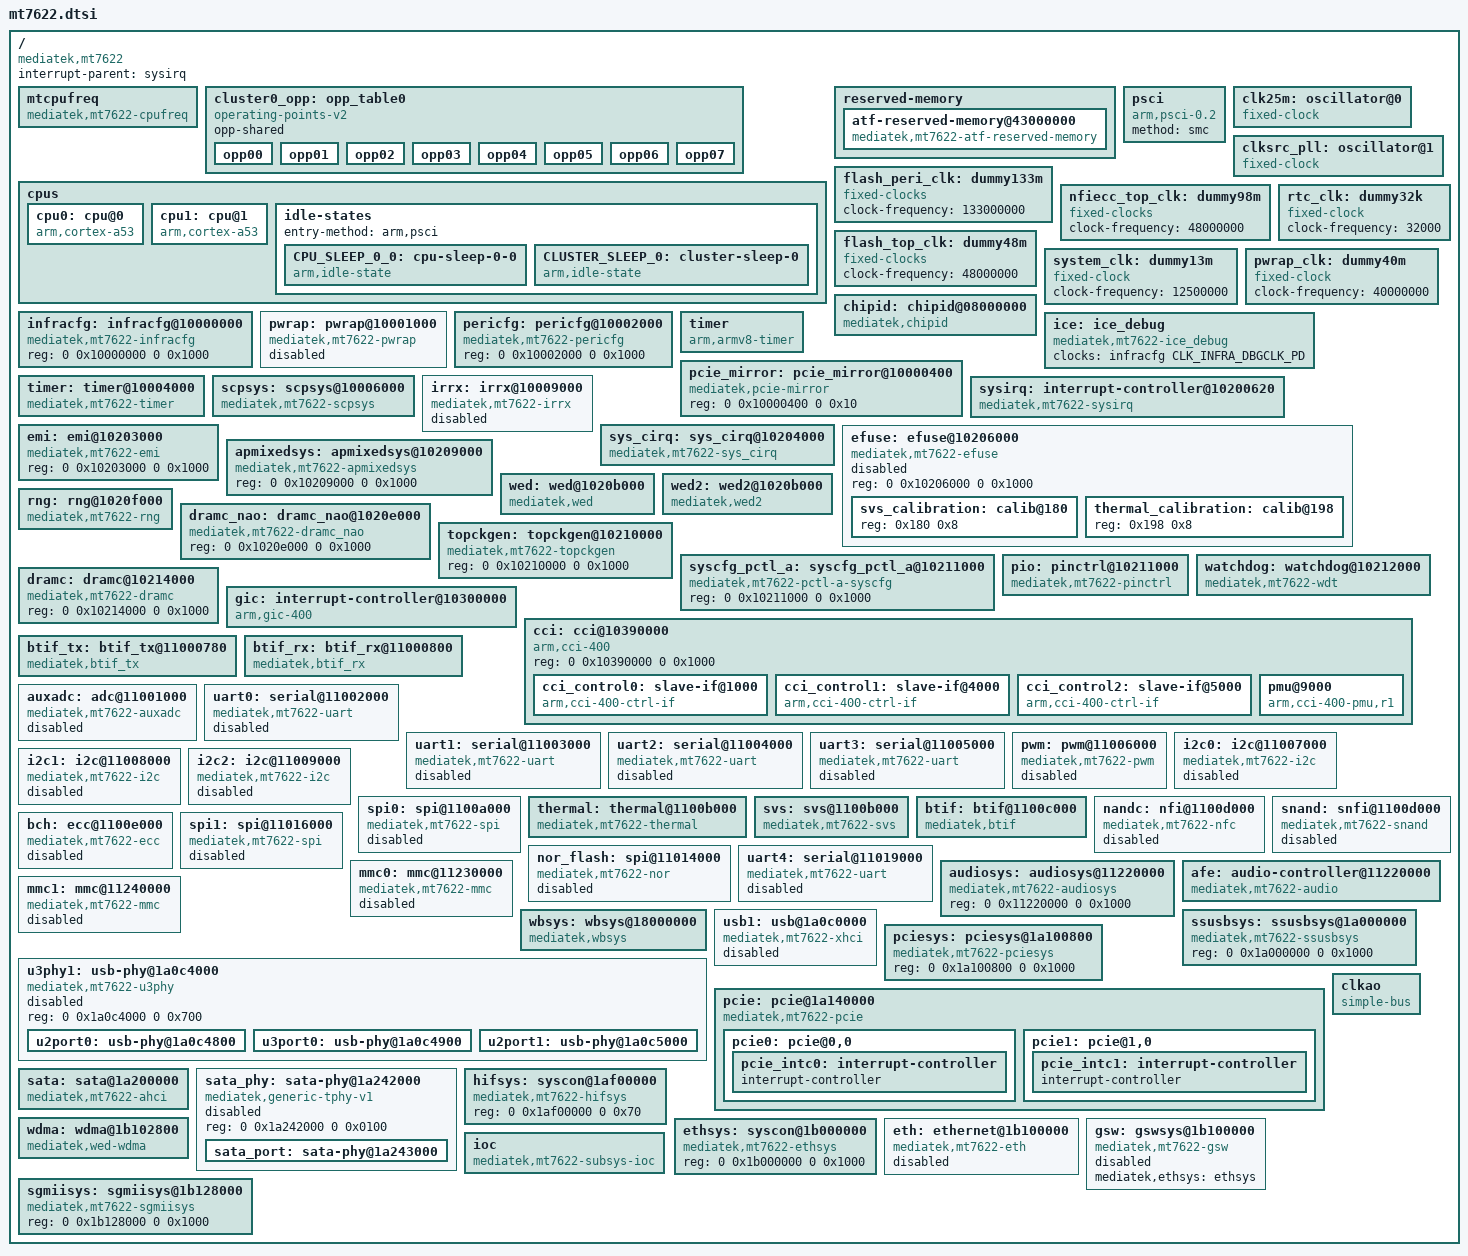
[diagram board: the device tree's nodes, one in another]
/*
 * Copyright (c) 2016 MediaTek Inc.
 * Author: Ming.Huang <ming.huang@mediatek.com>
 *
 * This program is free software; you can redistribute it and/or modify
 * it under the terms of the GNU General Public License version 2 as
 * published by the Free Software Foundation.
 *
 * This program is distributed in the hope that it will be useful,
 * but WITHOUT ANY WARRANTY; without even the implied warranty of
 * MERCHANTABILITY or FITNESS FOR A PARTICULAR PURPOSE.  See the
 * GNU General Public License for more details.
 */

#include <dt-bindings/clock/mt7622-clk.h>
#include <dt-bindings/interrupt-controller/irq.h>
#include <dt-bindings/interrupt-controller/arm-gic.h>
#include <dt-bindings/power/mt7622-power.h>
#include <dt-bindings/reset-controller/mt7622-resets.h>
#include <dt-bindings/phy/phy.h>
#include "mt7622-pinfunc.h"

/ {
	compatible = "mediatek,mt7622";
	interrupt-parent = <&sysirq>;
	#address-cells = <2>;
	#size-cells = <2>;

	mtcpufreq {
		compatible = "mediatek,mt7622-cpufreq";
	};

	cluster0_opp: opp_table0 {
		compatible = "operating-points-v2";
		opp-shared;
		opp00 {
			opp-hz = /bits/ 64 <300000000>;
			opp-microvolt = <950000>;
		};
		opp01 {
			opp-hz = /bits/ 64 <437500000>;
			opp-microvolt = <1000000>;
		};
		opp02 {
			opp-hz = /bits/ 64 <600000000>;
			opp-microvolt = <1050000>;
		};
		opp03 {
			opp-hz = /bits/ 64 <812500000>;
			opp-microvolt = <1100000>;
		};
		opp04 {
			opp-hz = /bits/ 64 <1025000000>;
			opp-microvolt = <1150000>;
		};
		opp05 {
			opp-hz = /bits/ 64 <1137500000>;
			opp-microvolt = <1200000>;
		};
		opp06 {
			opp-hz = /bits/ 64 <1262500000>;
			opp-microvolt = <1250000>;
		};
		opp07 {
			opp-hz = /bits/ 64 <1350000000>;
			opp-microvolt = <1310000>;
		};
	};

	cpus {
		#address-cells = <2>;
		#size-cells = <0>;

		cpu0: cpu@0 {
			device_type = "cpu";
			compatible = "arm,cortex-a53";
			reg = <0x0 0x0>;
			enable-method = "psci";
			cpu-idle-states = <&CLUSTER_SLEEP_0 &CLUSTER_SLEEP_0>,
				<&CPU_SLEEP_0_0 &CPU_SLEEP_0_0 &CPU_SLEEP_0_0>;
			clocks = <&infracfg CLK_INFRA_MUX1_SEL>,
				<&apmixedsys CLK_APMIXED_MAIN_CORE_EN>,
				<&apmixedsys CLK_APMIXED_ARMPLL>;
			clock-names = "cpu", "intermediate", "armpll";
			operating-points-v2 = <&cluster0_opp>;
			cpu-release-addr = <0x0 0x40000200>;
			clock-frequency = <1300000000>;
			cci-control-port = <&cci_control2>;
		};

		cpu1: cpu@1 {
			device_type = "cpu";
			compatible = "arm,cortex-a53";
			reg = <0x0 0x1>;
			enable-method = "psci";
			cpu-idle-states = <&CLUSTER_SLEEP_0 &CLUSTER_SLEEP_0>,
				<&CPU_SLEEP_0_0 &CPU_SLEEP_0_0 &CPU_SLEEP_0_0>;
			clocks = <&infracfg CLK_INFRA_MUX1_SEL>,
				<&apmixedsys CLK_APMIXED_MAIN_CORE_EN>,
				<&apmixedsys CLK_APMIXED_ARMPLL>;
			clock-names = "cpu", "intermediate", "armpll";
			operating-points-v2 = <&cluster0_opp>;
			cpu-release-addr = <0x0 0x40000200>;
			clock-frequency = <1300000000>;
			cci-control-port = <&cci_control2>;
		};

		idle-states {
			entry-method = "arm,psci";

			CPU_SLEEP_0_0: cpu-sleep-0-0 {
				compatible = "arm,idle-state";
				arm,psci-suspend-param = <0x0010000>;
				entry-latency-us = <600>;
				exit-latency-us = <600>;
				min-residency-us = <1200>;
			};

			CLUSTER_SLEEP_0: cluster-sleep-0 {
				compatible = "arm,idle-state";
				arm,psci-suspend-param = <0x1010000>;
				entry-latency-us = <800>;
				exit-latency-us = <1000>;
				min-residency-us = <2000>;
			};

		};
	};

	reserved-memory {
		#address-cells = <2>;
		#size-cells = <2>;
		ranges;

		atf-reserved-memory@43000000 {
			compatible = "mediatek,mt7622-atf-reserved-memory";
			no-map;
			reg = <0 0x43000000 0 0x100000>;
		};
	};

	psci {
		compatible  = "arm,psci-0.2";
		method      = "smc";
	};

	clk25m: oscillator@0 {
		compatible = "fixed-clock";
		#clock-cells = <0>;
		clock-frequency = <25000000>;
		clock-output-names = "clkxtal";
	};

	clksrc_pll: oscillator@1 {
		compatible = "fixed-clock";
		#clock-cells = <0>;
		clock-frequency = <25000000>;
		clock-output-names = "clksrc_pll";
	};

	flash_peri_clk: dummy133m {
		compatible = "fixed-clocks";
		clock-frequency = <133000000>;
		#clock-cells = <0>;
	};

	nfiecc_top_clk: dummy98m {
		compatible = "fixed-clocks";
		clock-frequency = <48000000>;
		#clock-cells = <0>;
	};

	flash_top_clk: dummy48m {
		compatible = "fixed-clocks";
		clock-frequency = <48000000>;
		#clock-cells = <0>;
	};

	system_clk: dummy13m {
		compatible = "fixed-clock";
		clock-frequency = <12500000>;
		#clock-cells = <0>;
	};

	rtc_clk: dummy32k {
		compatible = "fixed-clock";
		clock-frequency = <32000>;
		#clock-cells = <0>;
	};

	pwrap_clk: dummy40m {
		compatible = "fixed-clock";
		clock-frequency = <40000000>;
		#clock-cells = <0>;
	};

	chipid: chipid@08000000 {
		compatible = "mediatek,chipid";
		reg = <0 0x08000000 0 0x0004>,
		      <0 0x08000004 0 0x0004>,
		      <0 0x08000008 0 0x0004>,
		      <0 0x0800000c 0 0x0004>;
	};

	infracfg: infracfg@10000000 {
		compatible = "mediatek,mt7622-infracfg", "syscon";
		reg = <0 0x10000000 0 0x1000>;
		#clock-cells = <1>;
	};

	pwrap: pwrap@10001000 {
		compatible = "mediatek,mt7622-pwrap";
		reg = <0 0x10001000 0 0x250>;
		reg-names = "pwrap";
		clocks = <&infracfg CLK_INFRA_PMIC_PD>,<&pwrap_clk>;
		clock-names = "spi","wrap";
		status = "disabled";
	};

	pericfg: pericfg@10002000 {
		compatible = "mediatek,mt7622-pericfg", "syscon";
		reg = <0 0x10002000 0 0x1000>;
		#clock-cells = <1>;
	};

	ice: ice_debug {
		compatible ="mediatek,mt7622-ice_debug",
			    "mediatek,mt2701-ice_debug";
		clocks = <&infracfg CLK_INFRA_DBGCLK_PD>;
		clock-names = "ice_dbg";
	};

	timer {
		compatible = "arm,armv8-timer";
		interrupt-parent = <&gic>;
		interrupts = <GIC_PPI 13 (GIC_CPU_MASK_SIMPLE(4) | IRQ_TYPE_LEVEL_HIGH)>,
			     <GIC_PPI 14 (GIC_CPU_MASK_SIMPLE(4) | IRQ_TYPE_LEVEL_HIGH)>,
			     <GIC_PPI 11 (GIC_CPU_MASK_SIMPLE(4) | IRQ_TYPE_LEVEL_HIGH)>,
			     <GIC_PPI 10 (GIC_CPU_MASK_SIMPLE(4) | IRQ_TYPE_LEVEL_HIGH)>;
	};

	pcie_mirror: pcie_mirror@10000400 {
		compatible = "mediatek,pcie-mirror";
		reg = <0 0x10000400 0 0x10>;
	};

	timer: timer@10004000 {
		compatible = "mediatek,mt7622-timer",
			     "mediatek,mt6577-timer";
		reg = <0 0x10004000 0 0x80>;
		interrupts = <GIC_SPI 152 IRQ_TYPE_LEVEL_LOW>;
		clocks = <&infracfg CLK_INFRA_APXGPT_PD>, <&topckgen CLK_TOP_RTC>;
		clock-names = "system-clk", "rtc-clk";
	};

	scpsys: scpsys@10006000 {
		compatible = "mediatek,mt7622-scpsys", "syscon";
		#power-domain-cells = <1>;
		reg = <0 0x10006000 0 0x1000>;
		interrupts = <GIC_SPI 165 IRQ_TYPE_LEVEL_LOW>,
			     <GIC_SPI 166 IRQ_TYPE_LEVEL_LOW>,
			     <GIC_SPI 167 IRQ_TYPE_LEVEL_LOW>,
			     <GIC_SPI 168 IRQ_TYPE_LEVEL_LOW>;
		infracfg = <&infracfg>;
		clocks = <&topckgen CLK_TOP_RTC>, <&topckgen CLK_TOP_HIF_SEL>;
		clock-names = "spm_rtc", "hif_sel";
	};

	irrx: irrx@10009000 {
		compatible = "mediatek,mt7622-irrx";
		reg = <0 0x10009000 0 0x1000>;
		interrupts = <GIC_SPI 175 IRQ_TYPE_LEVEL_LOW>;
		clocks = <&infracfg CLK_INFRA_IRRX_PD>;
		clock-names = "irrx_clock";
		status = "disabled";
	};

	sysirq: interrupt-controller@10200620 {
		compatible = "mediatek,mt7622-sysirq",
			     "mediatek,mt6577-sysirq";
		interrupt-controller;
		#interrupt-cells = <3>;
		interrupt-parent = <&gic>;
		reg = <0 0x10200620 0 0x20>;
	};

	emi: emi@10203000 {
		compatible = "mediatek,mt7622-emi",
			     "mediatek,mt8127-emi";
		reg = <0 0x10203000 0 0x1000>;
	};

	sys_cirq: sys_cirq@10204000 {
		compatible = "mediatek,mt7622-sys_cirq",
			     "mediatek,sys_cirq";
		reg = <0 0x10204000 0 0x1000>;
		interrupts = <GIC_SPI 231 IRQ_TYPE_LEVEL_LOW>;
		mediatek,cirq_num = <169>;
		mediatek,spi_start_offset = <72>;
	};

	efuse: efuse@10206000 {
		compatible = "mediatek,mt7622-efuse",
			     "mediatek,efuse";
		reg = <0 0x10206000 0 0x1000>;
		#address-cells = <1>;
		#size-cells = <1>;
		status = "disabled";
		svs_calibration: calib@180 {
			reg = <0x180 0x8>;
		};
		thermal_calibration: calib@198 {
			reg = <0x198 0x8>;
		};
	};

	apmixedsys: apmixedsys@10209000 {
		compatible = "mediatek,mt7622-apmixedsys", "syscon";
		reg = <0 0x10209000 0 0x1000>;
		#clock-cells = <1>;
	};

	wed: wed@1020b000 {
		compatible = "mediatek,wed";
		wed_num = <2>;
		/* add this property for wed get the pci slot number. */
		pci_slot_map = <0>, <1>;
		reg = <0 0x1020a000 0 0x1000>,
		      <0 0x1020b000 0 0x1000>;
		interrupts = <GIC_SPI 214 IRQ_TYPE_LEVEL_LOW>,
			     <GIC_SPI 215 IRQ_TYPE_LEVEL_LOW>;
	};

	wed2: wed2@1020b000 {
		compatible = "mediatek,wed2";
		wed_num = <2>;
		reg = <0 0x1020a000 0 0x1000>,
		      <0 0x1020b000 0 0x1000>;
		interrupts = <GIC_SPI 214 IRQ_TYPE_LEVEL_LOW>,
			     <GIC_SPI 215 IRQ_TYPE_LEVEL_LOW>;
	};

	rng: rng@1020f000 {
		compatible = "mediatek,mt7622-rng",
			     "mediatek,mt7623-rng";
		reg = <0 0x1020f000 0 0x100>;
		clocks = <&infracfg CLK_INFRA_TRNG_PD>;
		clock-names = "rng";
	};

	dramc_nao: dramc_nao@1020e000 {
		compatible = "mediatek,mt7622-dramc_nao";
		reg = <0 0x1020e000 0 0x1000>;
	};

	topckgen: topckgen@10210000 {
		compatible = "mediatek,mt7622-topckgen", "syscon";
		reg = <0 0x10210000 0 0x1000>;
		#clock-cells = <1>;
	};

	syscfg_pctl_a: syscfg_pctl_a@10211000 {
			compatible = "mediatek,mt7622-pctl-a-syscfg", "syscon";
			reg = <0 0x10211000 0 0x1000>;
	};

	pio: pinctrl@10211000 {
			compatible = "mediatek,mt7622-pinctrl";
			reg = <0 0x10005000 0 0x1000>;
			mediatek,pctl-regmap = <&syscfg_pctl_a>;
			pins-are-numbered;
			gpio-controller;
			#gpio-cells = <2>;
			interrupt-controller;
			#interrupt-cells = <2>;
			interrupts = <GIC_SPI 153 IRQ_TYPE_LEVEL_HIGH>;
	};

	watchdog: watchdog@10212000 {
		compatible = "mediatek,mt7622-wdt",
			     "mediatek,mt6589-wdt";
		reg = <0 0x10212000 0 0x1000>;
		interrupts = <GIC_SPI 128 IRQ_TYPE_EDGE_FALLING>;
		#reset-cells = <1>;
	};

	dramc: dramc@10214000 {
		compatible = "mediatek,mt7622-dramc";
		reg = <0 0x10214000 0 0x1000>;
	};

	gic: interrupt-controller@10300000 {
		compatible = "arm,gic-400";
		interrupt-controller;
		#interrupt-cells = <3>;
		interrupt-parent = <&gic>;
		reg = <0 0x10310000 0 0x1000>,
		      <0 0x10320000 0 0x1000>,
		      <0 0x10340000 0 0x2000>,
		      <0 0x10360000 0 0x2000>;
	};

	cci: cci@10390000 {
		compatible = "arm,cci-400";
		#address-cells = <1>;
		#size-cells = <1>;
		reg = <0 0x10390000 0 0x1000>;
		ranges = <0 0 0x10390000 0x10000>;

		cci_control0: slave-if@1000 {
			compatible = "arm,cci-400-ctrl-if";
			interface-type = "ace-lite";
			reg = <0x1000 0x1000>;
		};

		cci_control1: slave-if@4000 {
			compatible = "arm,cci-400-ctrl-if";
			interface-type = "ace";
			reg = <0x4000 0x1000>;
		};

		cci_control2: slave-if@5000 {
			compatible = "arm,cci-400-ctrl-if";
			interface-type = "ace";
			reg = <0x5000 0x1000>;
		};

		pmu@9000 {
			compatible = "arm,cci-400-pmu,r1";
			reg = <0x9000 0x5000>;
			interrupts = <GIC_SPI 90 IRQ_TYPE_LEVEL_LOW>,
				     <GIC_SPI 91 IRQ_TYPE_LEVEL_LOW>,
				     <GIC_SPI 92 IRQ_TYPE_LEVEL_LOW>,
				     <GIC_SPI 93 IRQ_TYPE_LEVEL_LOW>,
				     <GIC_SPI 94 IRQ_TYPE_LEVEL_LOW>;
		};
	};

	btif_tx: btif_tx@11000780 {
		compatible = "mediatek,btif_tx";
		reg = <0 0x11000780 0 0x80>;
		interrupts = <GIC_SPI 111 IRQ_TYPE_LEVEL_LOW>;
	};

	btif_rx: btif_rx@11000800 {
		compatible = "mediatek,btif_rx";
		reg = <0 0x11000800 0 0x80>;
		interrupts = <GIC_SPI 112 IRQ_TYPE_LEVEL_LOW>;
	};

	auxadc: adc@11001000 {
		compatible = "mediatek,mt7622-auxadc";
		reg = <0 0x11001000 0 0x1000>;
		clocks = <&pericfg CLK_PERI_AUXADC_PD>;
		clock-names = "main";
		#io-channel-cells = <1>;
		status = "disabled";
	};

	uart0: serial@11002000 {
		compatible = "mediatek,mt7622-uart",
			     "mediatek,mt6577-uart";
		reg = <0 0x11002000 0 0x400>;
		interrupts = <GIC_SPI 91 IRQ_TYPE_LEVEL_LOW>;
		clocks = <&topckgen CLK_TOP_UART_SEL>, <&pericfg CLK_PERI_UART0_PD>;
		clock-names = "baud", "bus";
		status = "disabled";
	};

	uart1: serial@11003000 {
		compatible = "mediatek,mt7622-uart",
			     "mediatek,mt6577-uart";
		reg = <0 0x11003000 0 0x400>;
		interrupts = <GIC_SPI 92 IRQ_TYPE_LEVEL_LOW>;
		clocks = <&topckgen CLK_TOP_UART_SEL>, <&pericfg CLK_PERI_UART1_PD>;
		clock-names = "baud", "bus";
		status = "disabled";
	};

	uart2: serial@11004000 {
		compatible = "mediatek,mt7622-uart",
			     "mediatek,mt6577-uart";
		reg = <0 0x11004000 0 0x400>;
		interrupts = <GIC_SPI 93 IRQ_TYPE_LEVEL_LOW>;
		clocks = <&topckgen CLK_TOP_UART_SEL>, <&pericfg CLK_PERI_UART2_PD>;
		clock-names = "baud", "bus";
		status = "disabled";
	};

	uart3: serial@11005000 {
		compatible = "mediatek,mt7622-uart",
			     "mediatek,mt6577-uart";
		reg = <0 0x11005000 0 0x400>;
		interrupts = <GIC_SPI 94 IRQ_TYPE_LEVEL_LOW>;
		clocks = <&topckgen CLK_TOP_UART_SEL>, <&pericfg CLK_PERI_UART3_PD>;
		clock-names = "baud", "bus";
		status = "disabled";
	};


	pwm: pwm@11006000 {
		compatible = "mediatek,mt7622-pwm";
		reg = <0 0x11006000 0 0x1000>;
		interrupts = <GIC_SPI 77 IRQ_TYPE_LEVEL_LOW>;
		clocks = <&topckgen CLK_TOP_PWM_SEL>,
			 <&pericfg CLK_PERI_PWM_PD>,
			 <&pericfg CLK_PERI_PWM1_PD>,
			 <&pericfg CLK_PERI_PWM2_PD>,
			 <&pericfg CLK_PERI_PWM3_PD>,
			 <&pericfg CLK_PERI_PWM4_PD>,
			 <&pericfg CLK_PERI_PWM5_PD>,
			 <&pericfg CLK_PERI_PWM6_PD>;
		clock-names = "top",
			      "main",
			      "pwm1",
			      "pwm2",
			      "pwm3",
			      "pwm4",
			      "pwm5",
			      "pwm6";
		status = "disabled";
	};

	i2c0: i2c@11007000 {
		compatible = "mediatek,mt7622-i2c";
		reg = <0 0x11007000 0 0x90>,
		      <0 0x11000100 0 0x80>;
		interrupts = <GIC_SPI 84 IRQ_TYPE_LEVEL_LOW>;
		clock-div = <16>;
		clocks = <&pericfg CLK_PERI_I2C0_PD>,
			 <&pericfg CLK_PERI_AP_DMA_PD>;
		clock-names = "main", "dma";
		#address-cells = <1>;
		#size-cells = <0>;
		status = "disabled";
	};

	i2c1: i2c@11008000 {
		compatible = "mediatek,mt7622-i2c";
		reg = <0 0x11008000 0 0x90>,
		      <0 0x11000180 0 0x80>;
		interrupts = <GIC_SPI 85 IRQ_TYPE_LEVEL_LOW>;
		clock-div = <16>;
		clocks = <&pericfg CLK_PERI_I2C1_PD>,
			 <&pericfg CLK_PERI_AP_DMA_PD>;
		clock-names = "main", "dma";
		#address-cells = <1>;
		#size-cells = <0>;
		status = "disabled";
	};

	i2c2: i2c@11009000 {
		compatible = "mediatek,mt7622-i2c";
		reg = <0 0x11009000 0 0x90>,
		      <0 0x11000200 0 0x80>;
		interrupts = <GIC_SPI 86 IRQ_TYPE_LEVEL_LOW>;
		clock-div = <16>;
		clocks = <&pericfg CLK_PERI_I2C2_PD>,
			 <&pericfg CLK_PERI_AP_DMA_PD>;
		clock-names = "main", "dma";
		#address-cells = <1>;
		#size-cells = <0>;
		status = "disabled";
	};

	spi0: spi@1100a000 {
		compatible = "mediatek,mt7622-spi";
		#address-cells = <1>;
		#size-cells = <0>;
		reg = <0 0x1100a000 0 0x100>;
		interrupts = <GIC_SPI 118 IRQ_TYPE_LEVEL_LOW>;
		clocks = <&topckgen CLK_TOP_SYSPLL3_D2>,
			 <&topckgen CLK_TOP_SPI0_SEL>,
			 <&pericfg CLK_PERI_SPI0_PD>;
		clock-names = "parent-clk", "sel-clk", "spi-clk";
		status = "disabled";
	};

	thermal: thermal@1100b000 {
		compatible = "mediatek,mt7622-thermal";
		reg = <0 0x1100b000 0 0x1000>;
		interrupts = <GIC_SPI 110 IRQ_TYPE_LEVEL_LOW>;
		clocks = <&pericfg CLK_PERI_THERM_PD>, <&pericfg CLK_PERI_AUXADC_PD>;
		clock-names = "therm", "auxadc";
		auxadc = <&auxadc>;
		apmixedsys = <&apmixedsys>;
		pericfg = <&pericfg>;
		nvmem-cells = <&thermal_calibration>;
		nvmem-cell-names = "calibration-data";
	};

	svs: svs@1100b000 {
		compatible = "mediatek,mt7622-svs";
		reg = <0 0x1100b000 0 0x1000>;
		interrupts = <GIC_SPI 125 IRQ_TYPE_LEVEL_LOW>;
		nvmem-cells = <&svs_calibration>;
		nvmem-cell-names = "svs_calibration";
	};

	btif: btif@1100c000 {
		compatible = "mediatek,btif";
		reg = <0 0x1100c000 0 0x1000>;
		interrupts = <GIC_SPI 90 IRQ_TYPE_LEVEL_LOW>, <GIC_SPI 126 IRQ_TYPE_LEVEL_LOW>;
		clocks = <&pericfg CLK_PERI_BTIF_PD>, <&pericfg CLK_PERI_AP_DMA_PD>;
		clock-names = "btifc", "apdmac";
	};

	nandc: nfi@1100d000 {
		compatible = "mediatek,mt7622-nfc";
		reg = <0 0x1100D000 0 0x1000>;
		interrupts = <GIC_SPI 96 IRQ_TYPE_LEVEL_LOW>;
		clocks = <&pericfg CLK_PERI_NFI_PD>, <&pericfg CLK_PERI_SNFI_PD>;
		clock-names = "nfi_clk", "pad_clk";
		ecc-engine = <&bch>;
		#address-cells = <1>;
		#size-cells = <0>;
		status = "disabled";
	};

	snand: snfi@1100d000 {
		compatible = "mediatek,mt7622-snand";
		reg = <0 0x1100d000 0 0x2000>;
		interrupts = <GIC_SPI 96 IRQ_TYPE_LEVEL_LOW>;
		clocks = <&pericfg CLK_PERI_NFI_PD>,
			 <&pericfg CLK_PERI_SNFI_PD>,
			 <&pericfg CLK_PERI_NFIECC_PD>;
		clock-names = "nfi_clk", "pad_clk", "nfiecc_clk";
		#address-cells = <1>;
		#size-cells = <0>;
		status = "disabled";
	};

	bch: ecc@1100e000 {
		compatible = "mediatek,mt7622-ecc";
		reg = <0 0x1100e000 0 0x1000>;
		interrupts = <GIC_SPI 95 IRQ_TYPE_LEVEL_LOW>;
		clocks = <&pericfg CLK_PERI_NFIECC_PD>;
		clock-names = "nfiecc_clk";
		status = "disabled";
	};

	nor_flash: spi@11014000 {
		compatible = "mediatek,mt7622-nor",
			     "mediatek,mt8173-nor";
		reg = <0 0x11014000 0 0xe0>;
		clocks = <&pericfg CLK_PERI_FLASH_PD>,
			 <&topckgen CLK_TOP_FLASH_SEL>;
		clock-names = "spi", "sf";
		#address-cells = <1>;
		#size-cells = <1>;
		status = "disabled";
	};

	spi1: spi@11016000 {
		compatible = "mediatek,mt7622-spi";
		#address-cells = <1>;
		#size-cells = <0>;
		reg = <0 0x11016000 0 0x100>;
		interrupts = <GIC_SPI 122 IRQ_TYPE_LEVEL_LOW>;
		clocks = <&topckgen CLK_TOP_SYSPLL3_D2>,
			 <&topckgen CLK_TOP_SPI1_SEL>,
			 <&pericfg CLK_PERI_SPI1_PD>;
		clock-names = "parent-clk", "sel-clk", "spi-clk";
		status = "disabled";
	};

	uart4: serial@11019000 {
		compatible = "mediatek,mt7622-uart",
			     "mediatek,mt6577-uart";
		reg = <0 0x11019000 0 0x400>;
		interrupts = <GIC_SPI 89 IRQ_TYPE_LEVEL_LOW>;
		clocks = <&topckgen CLK_TOP_UART_SEL>, <&pericfg CLK_PERI_UART4_PD>;
		clock-names = "baud", "bus";
		status = "disabled";
	};

	audiosys: audiosys@11220000 {
		compatible = "mediatek,mt7622-audiosys", "syscon";
		reg = <0 0x11220000 0 0x1000>;
		#clock-cells = <1>;
	};

	afe: audio-controller@11220000 {
		compatible = "mediatek,mt7622-audio";
		reg = <0 0x11220000 0 0x2000>,
			<0 0x112a0000 0 0x10000>;
		interrupts = <GIC_SPI 145 IRQ_TYPE_LEVEL_LOW>,
			<GIC_SPI 144 IRQ_TYPE_LEVEL_LOW>;
		clocks = <&infracfg CLK_INFRA_AUDIO_PD>,
			<&topckgen CLK_TOP_A1SYS_HP_SEL>,
			<&topckgen CLK_TOP_A2SYS_HP_SEL>,
			<&topckgen CLK_TOP_A1SYS_HP_DIV>,
			<&topckgen CLK_TOP_A2SYS_HP_DIV>,
			<&topckgen CLK_TOP_AUD1PLL>,
			<&topckgen CLK_TOP_AUD2PLL>,
			<&topckgen CLK_TOP_A1SYS_HP_DIV_PD>,
			<&topckgen CLK_TOP_A2SYS_HP_DIV_PD>,
			<&topckgen CLK_TOP_AUD_INTBUS_SEL>,
			<&topckgen CLK_TOP_SYSPLL1_D4>,
			<&topckgen CLK_TOP_INTDIR_SEL>,
			<&topckgen CLK_TOP_UNIVPLL_D2>,
			<&topckgen CLK_TOP_APLL1_SEL>,
			<&topckgen CLK_TOP_APLL2_SEL>,
			<&topckgen CLK_TOP_I2S0_MCK_SEL>,
			<&topckgen CLK_TOP_I2S1_MCK_SEL>,
			<&topckgen CLK_TOP_I2S2_MCK_SEL>,
			<&topckgen CLK_TOP_I2S3_MCK_SEL>,
			<&topckgen CLK_TOP_APLL1_DIV>,
			<&topckgen CLK_TOP_APLL2_DIV>,
			<&topckgen CLK_TOP_I2S0_MCK_DIV>,
			<&topckgen CLK_TOP_I2S1_MCK_DIV>,
			<&topckgen CLK_TOP_I2S2_MCK_DIV>,
			<&topckgen CLK_TOP_I2S3_MCK_DIV>,
			<&topckgen CLK_TOP_APLL1_DIV_PD>,
			<&topckgen CLK_TOP_APLL2_DIV_PD>,
			<&topckgen CLK_TOP_I2S0_MCK_DIV_PD>,
			<&topckgen CLK_TOP_I2S1_MCK_DIV_PD>,
			<&topckgen CLK_TOP_I2S2_MCK_DIV_PD>,
			<&topckgen CLK_TOP_I2S3_MCK_DIV_PD>,
			<&topckgen CLK_TOP_AUD1_SEL>,
			<&topckgen CLK_TOP_AUD2_SEL>,
			<&topckgen CLK_TOP_ASM_H_SEL>,
			<&topckgen CLK_TOP_ASM_M_SEL>,
			<&topckgen CLK_TOP_SYSPLL_D5>,
			<&topckgen CLK_TOP_UNIVPLL2_D2>,
			<&audiosys CLK_AUDIO_AFE>,
			<&audiosys CLK_AUDIO_APLL>,
			<&audiosys CLK_AUDIO_A1SYS>,
			<&audiosys CLK_AUDIO_A2SYS>;

		clock-names = "infra_audio_pd",
			"top_a1sys_hp_sel",
			"top_a2sys_hp_sel",
			"top_a1sys_div",
			"top_a2sys_div",
			"top_aud1pll_ck",
			"top_aud2pll_ck",
			"top_a1sys_div_pd",
			"top_a2sys_div_pd",
			"top_aud_intbus_sel",
			"top_syspll1_d4",
			"top_intdir_sel",
			"top_univpll_d2",
			"top_apll1_ck_sel",
			"top_apll2_ck_sel",
			"top_i2s0_mck_sel",
			"top_i2s1_mck_sel",
			"top_i2s2_mck_sel",
			"top_i2s3_mck_sel",
			"top_apll1_ck_div",
			"top_apll2_ck_div",
			"top_i2s0_mck_div",
			"top_i2s1_mck_div",
			"top_i2s2_mck_div",
			"top_i2s3_mck_div",
			"top_apll1_ck_div_pd",
			"top_apll2_ck_div_pd",
			"top_i2s0_mck_div_pd",
			"top_i2s1_mck_div_pd",
			"top_i2s2_mck_div_pd",
			"top_i2s3_mck_div_pd",
			"top_aud1_sel",
			"top_aud2_sel",
			"top_asm_h_sel",
			"top_asm_m_sel",
			"top_syspll_d5",
			"top_univpll2_d2",
			"top_audio_afe",
			"top_audio_apll",
			"top_audio_a1sys",
			"top_audio_a2sys";
	};

	mmc0: mmc@11230000 {
		compatible = "mediatek,mt7622-mmc";
		reg = <0 0x11230000 0 0x1000>;
		interrupts = <GIC_SPI 79 IRQ_TYPE_LEVEL_LOW>;
		clocks = <&pericfg CLK_PERI_MSDC30_0_PD>,
		       <&topckgen CLK_TOP_MSDC50_0_SEL>;
		clock-names = "source", "hclk";
		status = "disabled";
	};

	mmc1: mmc@11240000 {
		compatible = "mediatek,mt7622-mmc";
		reg = <0 0x11240000 0 0x1000>;
		interrupts = <GIC_SPI 80 IRQ_TYPE_LEVEL_LOW>;
		clocks = <&pericfg CLK_PERI_MSDC30_1_PD>,
		       <&topckgen CLK_TOP_AXI_SEL>;
		clock-names = "source", "hclk";
		status = "disabled";
	};

	wbsys: wbsys@18000000 {
		compatible = "mediatek,wbsys";
		reg = <0 0x18000000 0  0x100000>;
		interrupts = <GIC_SPI 211 IRQ_TYPE_LEVEL_LOW>;
		dma-coherent;
	};

	ssusbsys: ssusbsys@1a000000 {
		compatible = "mediatek,mt7622-ssusbsys", "syscon";
		reg = <0 0x1a000000 0 0x1000>;
		#clock-cells = <1>;
	};

	usb1: usb@1a0c0000 {
		compatible = "mediatek,mt7622-xhci", "mediatek,mt2701-xhci";
		reg = <0 0x1a0c0000 0 0x01000>,
		      <0 0x1a0c4700 0 0x0100>;
		reg-names = "mac", "ippc";
		interrupts = <GIC_SPI 232 IRQ_TYPE_LEVEL_LOW>;
		power-domains = <&scpsys MT7622_POWER_DOMAIN_HIF1>;
		clocks = <&ssusbsys CLK_SSUSB_SYS_EN>, <&ssusbsys CLK_SSUSB_REF_EN>,
			 <&ssusbsys CLK_SSUSB_MCU_EN>, <&ssusbsys CLK_SSUSB_DMA_EN>;
		clock-names = "sys_ck", "free_ck", "ahb_ck", "dma_ck";
		phys = <&u2port0 PHY_TYPE_USB2>,
			<&u3port0 PHY_TYPE_USB3>,
			<&u2port1 PHY_TYPE_USB2>;
		status = "disabled";
	};

	u3phy1: usb-phy@1a0c4000 {
		compatible = "mediatek,mt7622-u3phy", "mediatek,mt2701-u3phy";
		reg = <0 0x1a0c4000 0 0x700>;
		#address-cells = <2>;
		#size-cells = <2>;
		ranges;
		status = "disabled";

		u2port0: usb-phy@1a0c4800 {
			reg = <0 0x1a0c4800 0 0x0100>;
			#phy-cells = <1>;
			clocks = <&ssusbsys CLK_SSUSB_U2_PHY_EN>;
			clock-names = "ref";
		};

		u3port0: usb-phy@1a0c4900 {
			reg = <0 0x1a0c4900 0 0x0700>;
			#phy-cells = <1>;
			clocks = <&clk25m>;
			clock-names = "ref";
		};

		u2port1: usb-phy@1a0c5000 {
			reg = <0 0x1a0c5000 0 0x0100>;
			#phy-cells = <1>;
			clocks = <&ssusbsys CLK_SSUSB_U2_PHY_1P_EN>;
			clock-names = "ref";
		};
	};

	pciesys: pciesys@1a100800 {
		compatible = "mediatek,mt7622-pciesys", "syscon";
		reg = <0 0x1a100800 0 0x1000>;
		#clock-cells = <1>;
		#reset-cells = <1>;
	};

	pcie: pcie@1a140000 {
		compatible = "mediatek,mt7622-pcie";
		device_type = "pci";
		reg = <0 0x1a140000 0 0x1000>,
		      <0 0x1a143000 0 0x1000>,
		      <0 0x1a145000 0 0x1000>;
		reg-names = "subsys", "port0", "port1";
		#address-cells = <3>;
		#size-cells = <2>;
		interrupts = <GIC_SPI 228 IRQ_TYPE_LEVEL_LOW>,
			     <GIC_SPI 229 IRQ_TYPE_LEVEL_LOW>;
		clocks = <&pciesys CLK_PCIE_P0_MAC_EN>,
			 <&pciesys CLK_PCIE_P1_MAC_EN>,
			 <&pciesys CLK_PCIE_P0_AHB_EN>,
			 /* designer has connect rc1 with p0_ahb clock */
			 <&pciesys CLK_PCIE_P0_AHB_EN>,
			 <&pciesys CLK_PCIE_P0_AUX_EN>,
			 <&pciesys CLK_PCIE_P1_AUX_EN>,
			 <&pciesys CLK_PCIE_P0_AXI_EN>,
			 <&pciesys CLK_PCIE_P1_AXI_EN>,
			 <&pciesys CLK_PCIE_P0_OBFF_EN>,
			 <&pciesys CLK_PCIE_P1_OBFF_EN>,
			 <&pciesys CLK_PCIE_P0_PIPE_EN>,
			 <&pciesys CLK_PCIE_P1_PIPE_EN>;
		clock-names = "sys_ck0", "sys_ck1", "ahb_ck0", "ahb_ck1",
			      "aux_ck0", "aux_ck1", "axi_ck0", "axi_ck1",
			      "obff_ck0", "obff_ck1", "pipe_ck0", "pipe_ck1";
		power-domains = <&scpsys MT7622_POWER_DOMAIN_HIF0>;
		bus-range = <0x00 0xff>;
		ranges = <0x82000000 0 0x20000000  0x0 0x20000000  0 0x10000000>;
		pcie0: pcie@0,0 {
			device_type = "pci";
			reg = <0x0000 0 0 0 0>;
			#address-cells = <3>;
			#size-cells = <2>;
			#interrupt-cells = <1>;
			ranges;
			num-lanes = <1>;
			interrupt-map-mask = <0 0 0 7>;
			interrupt-map = <0 0 0 1 &pcie_intc0 0>,
					<0 0 0 2 &pcie_intc0 1>,
					<0 0 0 3 &pcie_intc0 2>,
					<0 0 0 4 &pcie_intc0 3>;
			pcie_intc0: interrupt-controller {
				interrupt-controller;
				#address-cells = <0>;
				#interrupt-cells = <1>;
			};
		};

		pcie1: pcie@1,0 {
			device_type = "pci";
			reg = <0x0800 0 0 0 0>;
			#address-cells = <3>;
			#size-cells = <2>;
			#interrupt-cells = <1>;
			ranges;
			num-lanes = <1>;
			interrupt-map-mask = <0 0 0 7>;
			interrupt-map = <0 0 0 1 &pcie_intc1 0>,
					<0 0 0 2 &pcie_intc1 1>,
					<0 0 0 3 &pcie_intc1 2>,
					<0 0 0 4 &pcie_intc1 3>;
			pcie_intc1: interrupt-controller {
				interrupt-controller;
				#address-cells = <0>;
				#interrupt-cells = <1>;
			};
		};
	};

	sata: sata@1a200000 {
		compatible = "mediatek,mt7622-ahci",
			     "mediatek,mtk-ahci";
		reg = <0 0x1a200000 0 0x1100>;
		interrupts = <GIC_SPI 233 IRQ_TYPE_LEVEL_HIGH>;
		interrupt-names = "hostc";
		clocks = <&apmixedsys CLK_APMIXED_ETH1PLL>,
			 <&pciesys CLK_SATA_AHB_EN>,
			 <&pciesys CLK_SATA_AXI_EN>,
			 <&pciesys CLK_SATA_ASIC_EN>,
			 <&pciesys CLK_SATA_RBC_EN>,
			 <&pciesys CLK_SATA_PM_EN>;
		clock-names = "pll", "ahb", "axi", "asic", "rbc", "pm";
		phys = <&sata_port PHY_TYPE_SATA>;
		phy-names = "sata-phy";
		ports-implemented = <0x1>;
		power-domains = <&scpsys MT7622_POWER_DOMAIN_HIF0>;
		resets = <&pciesys MT7622_SATA_AXI_BUS_RST>,
			 <&pciesys MT7622_SATA_PHY_SW_RST>,
			 <&pciesys MT7622_SATA_PHY_REG_RST>;
		reset-names = "axi", "sw", "reg";
		mediatek,phy-mode = <&pciesys>;
	};

	sata_phy: sata-phy@1a242000 {
		compatible = "mediatek,generic-tphy-v1";
		reg = <0 0x1a242000 0 0x0100>;
		#address-cells = <2>;
		#size-cells = <2>;
		ranges;
		status = "disabled";

		sata_port: sata-phy@1a243000 {
			reg = <0 0x1a243000 0 0x0100>;
			clocks = <&pciesys CLK_SATA_AHB_EN>;
			clock-names = "ref";
			#phy-cells = <1>;
		};
	};

	hifsys: syscon@1af00000 {
		compatible = "mediatek,mt7622-hifsys", "syscon";
		reg = <0 0x1af00000 0 0x70>;
	};

	ethsys: syscon@1b000000 {
		#address-cells = <1>;
		#size-cells = <1>;
		compatible = "mediatek,mt7622-ethsys",
			     "syscon";
		reg = <0 0x1b000000 0 0x1000>;
		#clock-cells = <1>;
	};

	eth: ethernet@1b100000 {
		compatible = "mediatek,mt7622-eth";
		reg = <0 0x1b100000 0 0x20000>;
		interrupts = <GIC_SPI 223 IRQ_TYPE_LEVEL_LOW>,
			     <GIC_SPI 224 IRQ_TYPE_LEVEL_LOW>,
			     <GIC_SPI 225 IRQ_TYPE_LEVEL_LOW>,
			     <GIC_SPI 240 IRQ_TYPE_LEVEL_LOW>;
		clocks = <&topckgen CLK_TOP_ETH_SEL>,
			 <&apmixedsys CLK_APMIXED_ETH1PLL>,
			 <&apmixedsys CLK_APMIXED_ETH2PLL>,
			 <&apmixedsys CLK_APMIXED_SGMIPLL>,
			 <&clk25m>,
			 <&ethsys CLK_ETH_ESW_EN>,
			 <&ethsys CLK_ETH_GP2_EN>,
			 <&ethsys CLK_ETH_GP1_EN>,
			 <&ethsys CLK_ETH_GP0_EN>,
			 <&sgmiisys CLK_SGMII_TX250M_EN>,
			 <&sgmiisys CLK_SGMII_RX250M_EN>,
			 <&sgmiisys CLK_SGMII_CDR_REF>,
			 <&sgmiisys CLK_SGMII_CDR_FB>;
		clock-names = "ethif", "eth1pll", "eth2pll",
			      "sgmipll", "trgpll", "esw", "gp2",
			      "gp1", "gp0", "sgmii_tx250m",
			      "sgmii_rx250m", "sgmii_cdr_ref",
			      "sgmii_cdr_fb";
		power-domains = <&scpsys MT7622_POWER_DOMAIN_ETHSYS>;
		mediatek,ethsys = <&ethsys>;
		mediatek,switch = <&gsw>;
		#reset-cells = <1>;
		#address-cells = <1>;
		#size-cells = <0>;
		status = "disabled";
	};

	gsw: gswsys@1b100000 {
		compatible = "mediatek,mt7622-gsw";
		mediatek,ethsys = <&ethsys>;
		status = "disabled";
	};

	wdma: wdma@1b102800 {
		compatible = "mediatek,wed-wdma";
		reg = <0 0x1b102800 0 0x400>,
		      <0 0x1b102c00 0 0x400>;
		interrupts = <GIC_SPI 216 IRQ_TYPE_LEVEL_LOW>,
			     <GIC_SPI 217 IRQ_TYPE_LEVEL_LOW>,
			     <GIC_SPI 218 IRQ_TYPE_LEVEL_LOW>,
			     <GIC_SPI 219 IRQ_TYPE_LEVEL_LOW>,
			     <GIC_SPI 220 IRQ_TYPE_LEVEL_LOW>,
			     <GIC_SPI 221 IRQ_TYPE_LEVEL_LOW>;
	};

	sgmiisys: sgmiisys@1b128000 {
		compatible = "mediatek,mt7622-sgmiisys", "syscon";
		reg = <0 0x1b128000 0 0x1000>;
		#clock-cells = <1>;
	};

	clkao: clkao {
		compatible = "simple-bus";
	};

	ioc {
		compatible = "mediatek,mt7622-subsys-ioc";
		mediatek,wbsys = <&infracfg>;
		mediatek,hifsys = <&hifsys>;
		mediatek,ethsys = <&ethsys>;
		mediatek,eth = <&eth>;

		mediatek,en_usb;
		mediatek,en_pcie_sata;
		mediatek,en_eth;
		mediatek,en_wifi;
	};
};

#include "mt7622-clkao.dtsi"
